# D1H register map
Vendor: Allwinner; File version: 1.0
Registers are 32-bit, read-write, reset 0x0 unless marked. A register's access mark holds for its fields unless they carry their own. Offsets are from the block's base; [hi:lo] are bit positions; {n}, {i} and the like mark numbered series.

## LRADC — Low Rate ADC
Base 0x02009800
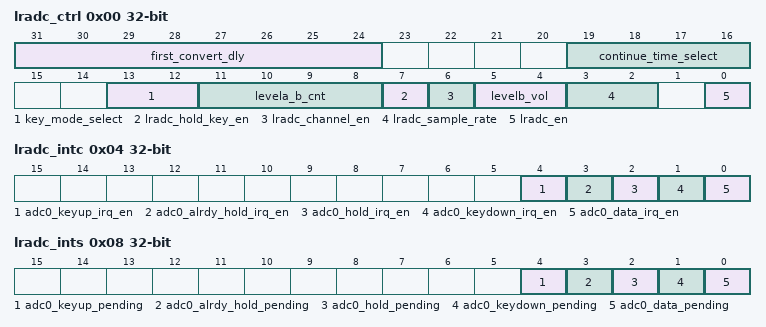
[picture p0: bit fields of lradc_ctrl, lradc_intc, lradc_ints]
0x00 lradc_ctrl — LRADC Control Register
  [31:24] first_convert_dly — ADC First Convert Delay Setting
  [19:16] continue_time_select — Continuous Mode Time Select
  [13:12] key_mode_select
    0=NORMAL; 1=SINGLE; 2=CONTINUOUS
  [11:8] levela_b_cnt — Level A to B time threshold select
  [7] lradc_hold_key_en — LRADC Hold Key Enable
    0=DISABLE; 1=ENABLE
  [6] lradc_channel_en — LRADC Channel Enable
    0=DISABLE; 1=ENABLE
  [5:4] levelb_vol — Level B Corresponding Data Value Setting (the real voltage value)
    1=V39 (1.221 V); 2=V36 (1.157 V); 3=V33 (1.093 V)
  [3:2] lradc_sample_rate
    0=R2K (2kHz); 1=R1K (1kHz); 2=R500 (500Hz); 3=R250 (250Hz)
  [0] lradc_en — LRADC Enable
    0=DISABLE; 1=ENABLE
0x04 lradc_intc — LRADC Interrupt Control Register
  [all] fields
    0=DISABLE; 1=ENABLE
  [4] adc0_keyup_irq_en — ADC0 Key Up Interrupt Enable
  [3] adc0_alrdy_hold_irq_en — ADC0 Already Hold Key Interrupt Enable
  [2] adc0_hold_irq_en — ADC0 Hold Key Interrupt Enable
  [1] adc0_keydown_irq_en — ADC0 Key Down Interrupt Enable
  [0] adc0_data_irq_en — ADC0 Data Interrupt Enable
0x08 lradc_ints — LRADC Interrupt Status Register
  [all] fields
    0=NO_PENDING; 1=PENDING
  [4] adc0_keyup_pending write-1-clears
  [3] adc0_alrdy_hold_pending write-1-clears — ADC0 Already Hold Key Pending
  [2] adc0_hold_pending write-1-clears — ADC0 Hold Key Pending
  [1] adc0_keydown_pending write-1-clears
  [0] adc0_data_pending write-1-clears
0x0C lradc_data ro
  [5:0] lradc_data

## LEDC
Base 0x02008000
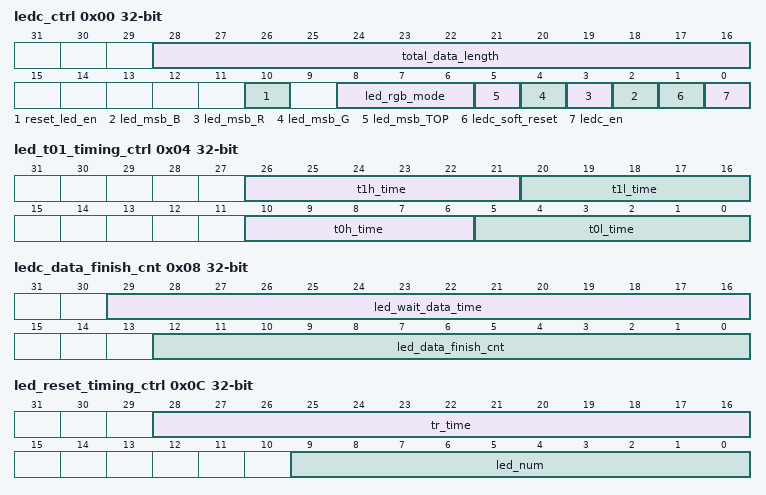
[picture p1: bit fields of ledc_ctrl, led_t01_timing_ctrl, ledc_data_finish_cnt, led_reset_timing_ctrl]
0x00 ledc_ctrl — LEDC Control Register
  [28:16] total_data_length
  [10] reset_led_en
  [8:6] led_rgb_mode
    0=GRB; 1=GBR; 2=RGB; 3=RBG; 4=BGR; 5=BRG
  [2] led_msb_{x} (x=B,R,G,TOP; step 1)
    0=LSB; 1=MSB
  [1] ledc_soft_reset
  [0] ledc_en
    0=DISABLE; 1=ENABLE
0x04 led_t01_timing_ctrl — LEDC T0 T1 Timing Control Register
  [26:21] t1h_time, [20:16] t1l_time, [10:6] t0h_time, [5:0] t0l_time range 0..31
0x08 ledc_data_finish_cnt — LEDC Data Finish Counter Register
  [29:16] led_wait_data_time range 0..8191, [12:0] led_data_finish_cnt ro
0x0C led_reset_timing_ctrl — LEDC Reset Timing Control Register
  [28:16] tr_time range 1..8191, [9:0] led_num
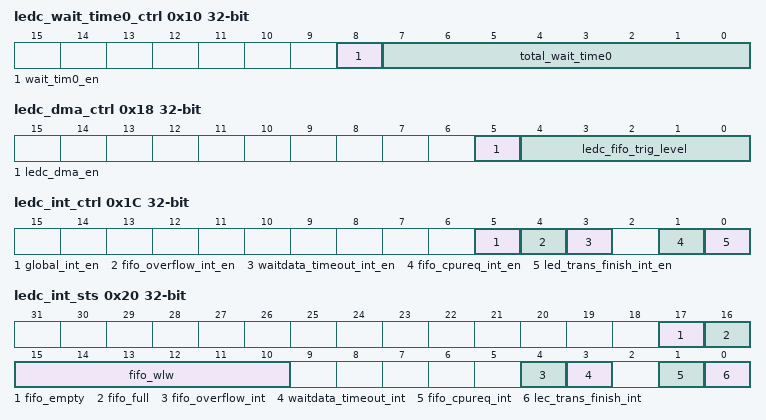
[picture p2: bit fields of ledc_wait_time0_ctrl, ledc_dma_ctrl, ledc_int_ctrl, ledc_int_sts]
0x10 ledc_wait_time0_ctrl — LEDC Wait Time0 Control Register
  [8] wait_tim0_en
    0=DISABLE; 1=ENABLE
  [7:0] total_wait_time0 range 1..255
0x14 ledc_data wo
0x18 ledc_dma_ctrl — LEDC DMA Control Register
  [5] ledc_dma_en
    0=DISABLE; 1=ENABLE
  [4:0] ledc_fifo_trig_level
0x1C ledc_int_ctrl — LEDC Interrupt Control Register
  [all] fields
    0=DISABLE; 1=ENABLE
  [5] global_int_en
  [4] fifo_overflow_int_en
  [3] waitdata_timeout_int_en
  [1] fifo_cpureq_int_en
  [0] led_trans_finish_int_en
0x20 ledc_int_sts — LEDC Interrupt Status Register
  [17] fifo_empty ro
  [16] fifo_full ro
  [15:10] fifo_wlw ro
  [4] fifo_overflow_int write-1-clears
    0=NOT_OVERFLOW; 1=OVERFLOW
  [3] waitdata_timeout_int write-1-clears
    0=NOT_TIMEOUT; 1=TIMEOUT
  [1] fifo_cpureq_int write-1-clears
    0=NOT_REQUEST; 1=REQUEST
  [0] lec_trans_finish_int write-1-clears
    0=NOT_TRANS_COMPLETE; 1=TRANS_COMPLETE
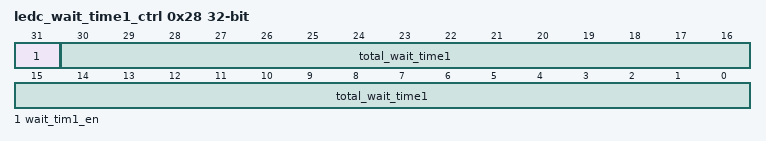
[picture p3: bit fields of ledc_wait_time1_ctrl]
0x28 ledc_wait_time1_ctrl — LEDC Wait Time1 Control Register
  [31] wait_tim1_en
    0=DISABLE; 1=ENABLE
  [30:0] total_wait_time1 range 128..2147483647
{0x30+4i} ledc_fifo_data{i} (i=0..31) ro

## CE_NS — Crypoto Engine
Base 0x03040000
0x00 ce_tda — Task Descriptor Address
  [31:0] task — Task Descriptor Address . Configure as the first address of the descriptor structure.
0x08 ce_icr (reset mask 0xF) — Interrupt Control Register
  [n+3:n] task{n}_irq_en (n=0..3) — Task Channel 3-0 Interrupt Enable
    0=DISABLE; 1=ENABLE
0x0C ce_isr (reset mask 0xF) — Interrupt Status Register
  [n+3:n] task{n}_pending (n=0..3) write-1-clears — Task Channel 3-0 End Pending . It indicates whether task is completed. . Write the corresponding channel bit of the register to clear the end flag.
    0=NOT_FINISHED (Task not finished); 1=FINISHED (Task finished)
0x10 ce_tlr — Task Load Register
  [0] task_load — Task Load . When set, the CE can load the descriptor of task if the task FIFO is not full.
0x14 ce_tsr — Task Status Register
  [1:0] running_channel_number ro
    {v}=T{v} (Task channel {v}) (v=0..3)
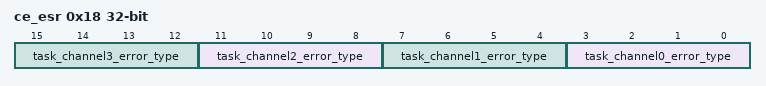
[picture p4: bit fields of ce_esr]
0x18 ce_esr (reset mask 0xFFFF) — Error Status Register
  [4n+3:4n] task_channel{n}_error_type (n=0..3) write-1-clears
    1=ALGORITHM_NOT_SUPPORT; 2=DATA_LENGTH_ERROR; 4=KEYSRAM_ACCESS_ERROR (keysram access error for AES)
0x24 ce_csa — Current Source Address Register
  [31:0] cur_src_addr ro — Current source address
0x28 ce_cda — Current Destination Address Register
  [31:0] cur_dst_addr ro — Current destination address
0x2C ce_tpr — Throughput Register
  [31:0] tp_num write-clears — It indicates the throughput writing to this register at last time. . Writing to this register will clear it to 0.
